# PY32F002Cxx register map
Vendor: Puya; Series: PY32F0; File version: 1.0.0
CPU: CM0+ r0p1, little endian, no MPU, no FPU, 4 interrupt priority bits
Registers are 32-bit, read-write, reset 0x0 unless marked. A register's access mark holds for its fields unless they carry their own. Offsets are from the block's base; [hi:lo] are bit positions; {n}, {i} and the like mark numbered series.

## GPIOA — General-purpose I/Os
Base 0x50000000
Same registers: GPIOB 0x50000400, GPIOC 0x50000800
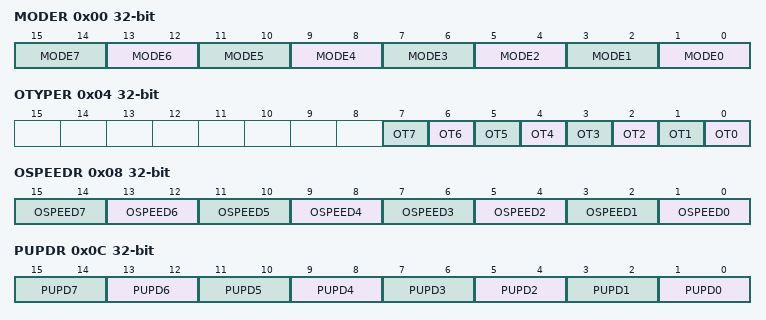
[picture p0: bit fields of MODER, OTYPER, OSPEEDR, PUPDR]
0x00 MODER — GPIO port mode register
  [all] fields
    1=0; 2=1
  [2n+1:2n] MODE{n} (n=0..7) — Port x configuration bits (y = 0..15)
0x04 OTYPER — GPIO port output type register
  [n] OT{n} (n=0..7) — Port x configuration bits (y = 0..15)
0x08 OSPEEDR — GPIO port output speed register
  [all] fields
    1=0; 2=1
  [2n+1:2n] OSPEED{n} (n=0..7) — Port x configuration bits (y = 0..15)
0x0C PUPDR — GPIO port pull-up/pull-down register
  [all] fields
    1=0; 2=1
  [2n+1:2n] PUPD{n} (n=0..7) — Port x configuration bits (y = 0..15)
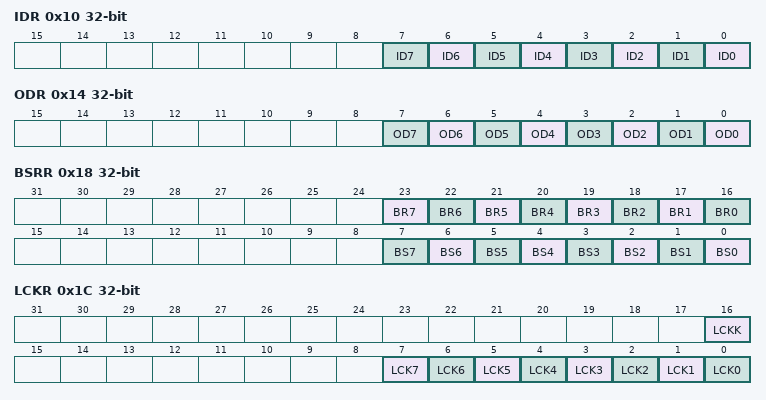
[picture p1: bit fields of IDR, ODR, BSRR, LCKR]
0x10 IDR — GPIO port input data register
  [n] ID{n} ro (n=0..7) — Port input data (y = 0..15)
0x14 ODR — GPIO port output data register
  [n] OD{n} (n=0..7) — Port output data (y = 0..15)
0x18 BSRR — GPIO port bit set/reset register
  [n+16] BR{n} (n=1..7) — Port x reset bit y (y = 0..15)
  [16] BR0 — Port x set bit y (y= 0..15)
  [n] BS{n} (n=0..7) — Port x set bit y (y= 0..15)
0x1C LCKR — GPIO port configuration lock register
  [16] LCKK — Port x lock bit y (y= 0..15)
  [n] LCK{n} (n=0..7) — Port x lock bit y (y= 0..15)
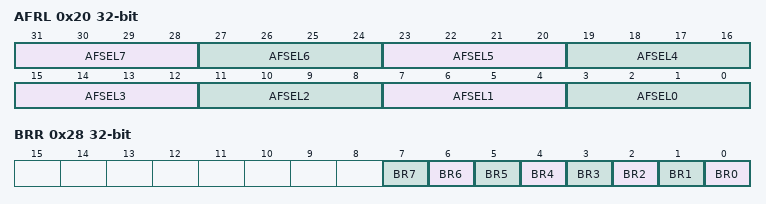
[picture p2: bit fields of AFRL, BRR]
0x20 AFRL — GPIO alternate function low register
  [31:28] AFSEL7 — Alternate function selection for port x bit y (y = 0..7)
    1=0; 2=1; 4=2
  [4n+3:4n] AFSEL{n} (n=0..6) — Alternate function selection for port x bit y (y = 0..7)
0x28 BRR — port bit reset register
  [n] BR{n} (n=0..7) — Port Reset bit

## GPIOD
Base 0x50000C00
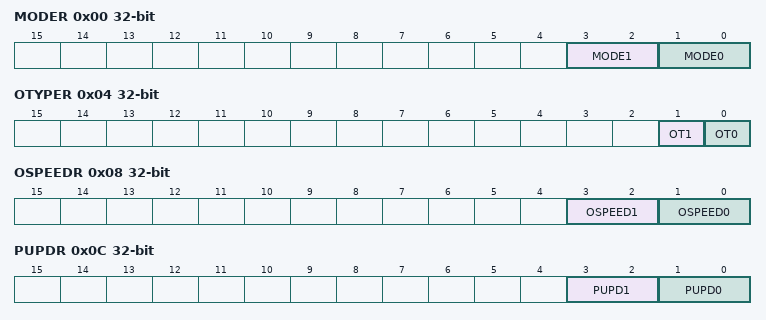
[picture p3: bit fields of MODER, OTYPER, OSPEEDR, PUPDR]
0x00 MODER
  [3:2] MODE1 — Port x configuration bits (y = 0..15)
    1=0; 2=1
  [1:0] MODE0 — Port x configuration bits (y = 0..15)
    1=0; 2=1
0x04 OTYPER
  [1] OT1 — Port x configuration bits (y = 0..15)
  [0] OT0 — Port x configuration bits (y = 0..15)
0x08 OSPEEDR
  [3:2] OSPEED1 — Port x configuration bits (y = 0..15)
    1=0; 2=1
  [1:0] OSPEED0 — Port x configuration bits (y = 0..15)
    1=0; 2=1
0x0C PUPDR
  [3:2] PUPD1 — Port x configuration bits (y = 0..15)
    1=0; 2=1
  [1:0] PUPD0 — Port x configuration bits (y = 0..15)
    1=0; 2=1
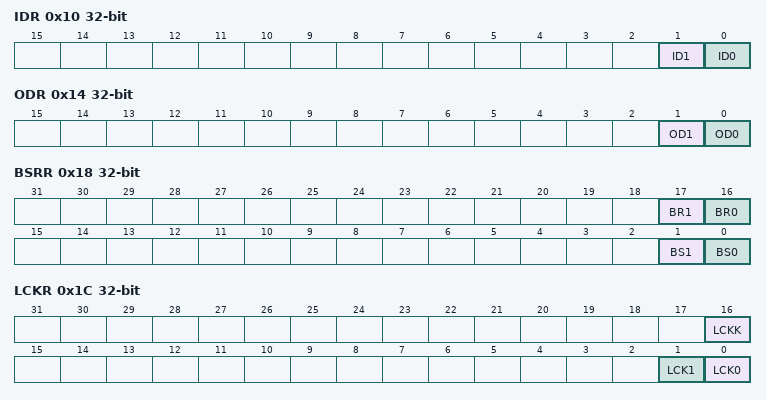
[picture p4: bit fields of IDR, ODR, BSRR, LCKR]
0x10 IDR
  [1] ID1 ro — Port input data (y = 0..15)
  [0] ID0 ro — Port input data (y = 0..15)
0x14 ODR
  [1] OD1 — Port output data (y = 0..15)
  [0] OD0 — Port output data (y = 0..15)
0x18 BSRR
  [17] BR1 — Port x reset bit y (y = 0..15)
  [16] BR0 — Port x set bit y (y= 0..15)
  [1] BS1 — Port x set bit y (y= 0..15)
  [0] BS0 — Port x set bit y (y= 0..15)
0x1C LCKR
  [16] LCKK — Port x lock bit y (y= 0..15)
  [1] LCK1 — Port x lock bit y (y= 0..15)
  [0] LCK0 — Port x lock bit y (y= 0..15)
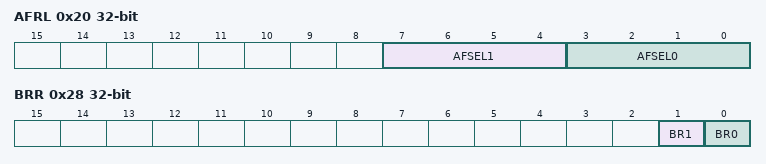
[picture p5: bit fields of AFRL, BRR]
0x20 AFRL
  [7:4] AFSEL1 — Alternate function selection for port x bit y (y = 0..7)
  [3:0] AFSEL0 — Alternate function selection for port x bit y (y = 0..7)
0x28 BRR
  [1] BR1 — Port Reset bit
  [0] BR0 — Port Reset bit

## I2C — Inter integrated circuit
Base 0x40005400
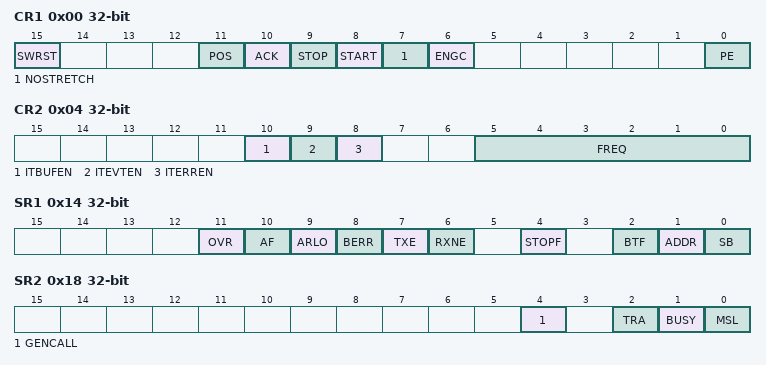
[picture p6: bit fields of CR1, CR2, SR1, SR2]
0x00 CR1 — Control register 1
  [15] SWRST — Software reset
  [11] POS — Acknowledge/PEC Position (for datareception)
  [10] ACK — Acknowledge enable
  [9] STOP — Stop generation
  [8] START — Start generation
  [7] NOSTRETCH — Clock stretching disable (Slavemode)
  [6] ENGC — General call enable
  [0] PE — Peripheral enable
0x04 CR2 — Control register 2
  [10] ITBUFEN — Buffer interrupt enable
  [9] ITEVTEN — Event interrupt enable
  [8] ITERREN — Error interrupt enable
  [5:0] FREQ — Peripheral clock frequency
    1=0; 2=1; 4=2; 8=3; 16=4; 32=5
0x08 OAR1 — Own address register 1
  [7:1] ADD — Interface address
0x10 DR — Data register
  [7:0] DR — 8-bit data register
    1=0; 2=1; 4=2; 8=3; 16=4; 32=5; 64=6; 128=7
0x14 SR1 — Status register 1
  [11] OVR — Overrun/Underrun
  [10] AF — Acknowledge failure
  [9] ARLO — Arbitration lost (mastermode)
  [8] BERR — Bus error
  [7] TXE ro — Data register empty(transmitters)
  [6] RXNE ro — Data register not empty(receivers)
  [4] STOPF ro — Stop detection (slavemode)
  [2] BTF ro — Byte transfer finished
  [1] ADDR ro — Address sent (master mode)/matched(slave mode)
  [0] SB ro — Start bit (Master mode)
0x18 SR2 — Status register 2
  [4] GENCALL ro — General call address (Slavemode)
  [2] TRA ro — Transmitter/receiver
  [1] BUSY ro — Bus busy
  [0] MSL ro — Master/slave
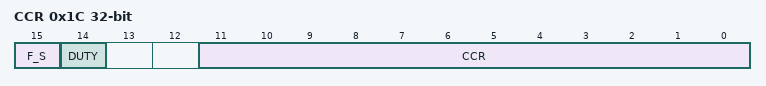
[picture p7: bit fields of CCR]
0x1C CCR — Clock control register
  [15] F_S — I2C master mode selection
  [14] DUTY — Fast mode duty cycle
  [11:0] CCR — Clock control register in Fast/Standardmode (Master mode)
0x20 TRISE
  [5:0] TRISE — Maximum rise time in Fast/Standard mode(Master mode)
